# RS1xxxx register map
Vendor: Silicon Lab Inc.; Series: ARMCM4; File version: 1.2
CPU: CM4 r1p0, little endian, MPU, FPU, 6 interrupt priority bits
Registers are 32-bit, read-write, reset 0x0 unless marked. A register's access mark holds for its fields unless they carry their own. Offsets are from the block's base; [hi:lo] are bit positions.

## Low_Power_Domain — The use of this is to store some information in ULP over wake-ups to reduce wake-up time
Base 0x24048400
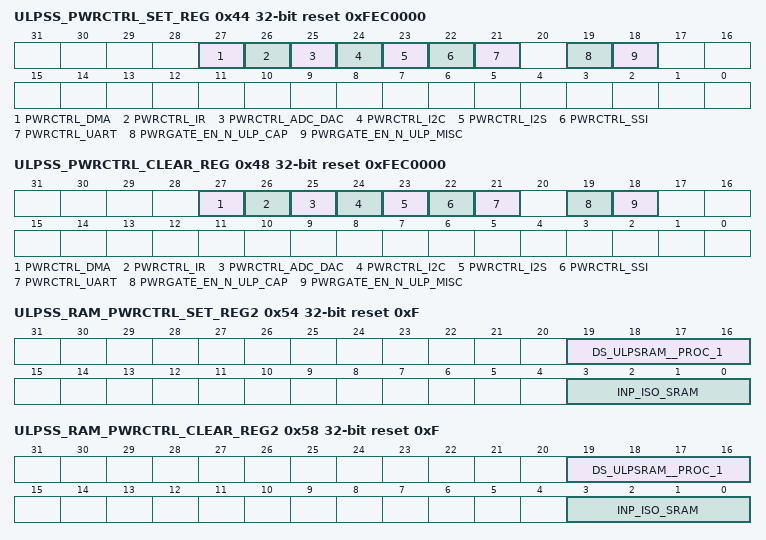
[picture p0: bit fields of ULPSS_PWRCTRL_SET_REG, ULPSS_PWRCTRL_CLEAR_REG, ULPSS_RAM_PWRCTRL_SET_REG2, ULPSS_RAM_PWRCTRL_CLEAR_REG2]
0x44 ULPSS_PWRCTRL_SET_REG reset 0xFEC0000 — ULPSS power control set register
  [27] PWRCTRL_DMA — Enables power to the DMA
    0=Disable (This has no effect.); 1=Enable (this enables power to the DMA)
  [26] PWRCTRL_IR — Enables power to the IR
    0=Disable (This has no effect.); 1=Enable (this enables power to the IR.)
  [25] PWRCTRL_ADC_DAC — Enables power to the ADC/DAC
    0=Disable (This has no effect.); 1=Enable (this enables power to the ADC/DAC.)
  [24] PWRCTRL_I2C — Enables power to the I2C
    0=Disable (This has no effect.); 1=Enable (this enables power to the I2C.)
  [23] PWRCTRL_I2S — Enables power to the I2S
    0=Disable (This has no effect.); 1=Enable (this enables power to the I2S.)
  [22] PWRCTRL_SSI — Enables power to the SPI/SSI
    0=Disable (This has no effect.); 1=Enable (this enables power to the SPI/SSI.)
  [21] PWRCTRL_UART — Enables power to the UART
    0=Disable (This has no effect.); 1=Enable (this enables power to the UART.)
  [19] PWRGATE_EN_N_ULP_CAP — Enables power to the ULPSS CAP
    0=Disable (This has no effect.); 1=Enable (this enables power to the ULPSS CAP.)
  [18] PWRGATE_EN_N_ULP_MISC — Enables power to the MISC.
    0=Disable (This has no effect.); 1=Enable (This enables power to the MISC.)
0x48 ULPSS_PWRCTRL_CLEAR_REG reset 0xFEC0000 — ULPSS power control clear register
  [27] PWRCTRL_DMA — Disables power to the DMA
    0=Disable (This has no effect.); 1=Enable (This disables power to the DMA)
  [26] PWRCTRL_IR — Disables power to the IR
    0=Disable (This has no effect.); 1=Enable (This disables power to the IR)
  [25] PWRCTRL_ADC_DAC — Disables power to the ADC/DAC
    0=Disable (This has no effect.); 1=Enable (This disables power to the ADC/DAC)
  [24] PWRCTRL_I2C — Disables power to the I2C
    0=Disable (This has no effect.); 1=Enable (This disables power to the I2C)
  [23] PWRCTRL_I2S — Disables power to the I2S
    0=Disable (This has no effect.); 1=Enable (This disables power to the I2S)
  [22] PWRCTRL_SSI — Disables power to the SPI/SSI
    0=Disable (This has no effect.); 1=Enable (This disables power to the SPI/SSI)
  [21] PWRCTRL_UART — Disables power to the UART
    0=Disable (This has no effect.); 1=Enable (This disables power to the UART)
  [19] PWRGATE_EN_N_ULP_CAP — Disables power to the ULPSS CAP.
    0=Disable (This has no effect.); 1=Enable (This disables power to the ULPSS CAP)
  [18] PWRGATE_EN_N_ULP_MISC — Disables power to the MISC.
    0=Disable (This has no effect.); 1=Enable (This disables power to the MISC)
0x4C ULPSS_RAM_PWRCTRL_SET_REG1 reset 0xF — ULPSS ram power control set register1
  [3:0] PWRCTRL1_ULP_SRAM — Enables power to the ULP SRAM.
    0=Disable (This has no effect.); 1=Enable (this enables power to ULP-SRAM)
0x50 ULPSS_RAM_PWRCTRL_CLEAR_REG1 reset 0xF — ULPSS ram power control clear register1
  [3:0] PWRCTRL1_ULP_SRAM — Disables power to the ULP SRAM.
    0=Disable (This has no effect.); 1=Enable (this disables power to the ULP-SRAM)
0x54 ULPSS_RAM_PWRCTRL_SET_REG2 reset 0xF — ULPSS ram power control set register2
  [19:16] DS_ULPSRAM__PROC_1 — Deep-Sleep control for ULPTASS SRAM
    0=Disable (This has no effect.); 1=Enable (This enables deep sleep mode ULPTASS SRAM.)
  [3:0] INP_ISO_SRAM — Input isolation control for ULPTASS SRAM
    0=Disable (This has no effect.); 1=Enable (This enables isolation to ULPTASS SRAM.)
0x58 ULPSS_RAM_PWRCTRL_CLEAR_REG2 reset 0xF — ULPSS ram power control clear register2
  [19:16] DS_ULPSRAM__PROC_1 — Deep-Sleep control for ULPTASS SRAM
    0=Disable (This has no effect.); 1=Enable (This disables deep sleep mode ULPTASS SRAM.)
  [3:0] INP_ISO_SRAM — Input isolation control for ULPTASS SRAM
    0=Disable (This has no effect.); 1=Enable (This disables isolation to ULPTASS SRAM.)
0x5C ULPSS_RAM_PWRCTRL_SET_REG3 reset 0xF — ULPSS ram power control set register3
  [3:0] PWRCTRL_ULPTASS_SRAM_PERI_1 — Power Control signal for ULPTASS SRAM Dual Rail pins
    0=Disable (This has no effect.); 1=Enable (This enables power to ULPTASS SRAM dual rail pins)
0x60 ULPSS_RAM_PWRCTRL_CLEAR_REG3 reset 0xF — ULPSS ram power control clear register3
  [3:0] PWRCTRL_ULPTASS_SRAM_PERI_1 — Power Control signal for ULPTASS SRAM Dual Rail pins
    0=Disable (This has no effect.); 1=Enable (This disables power to ULPTASS SRAM dual rail pins)
